VERSION ""

NS_ :

BS_:

BU_: XXX

BO_ 85 CID_YLHISD: 8 XXX
 SG_ sig_fvpfgf : 40|1@1+ (1,0) [0|1] "" XXX
 SG_ sig_tsgliz : 56|8@1+ (1,0) [0|255] "" XXX

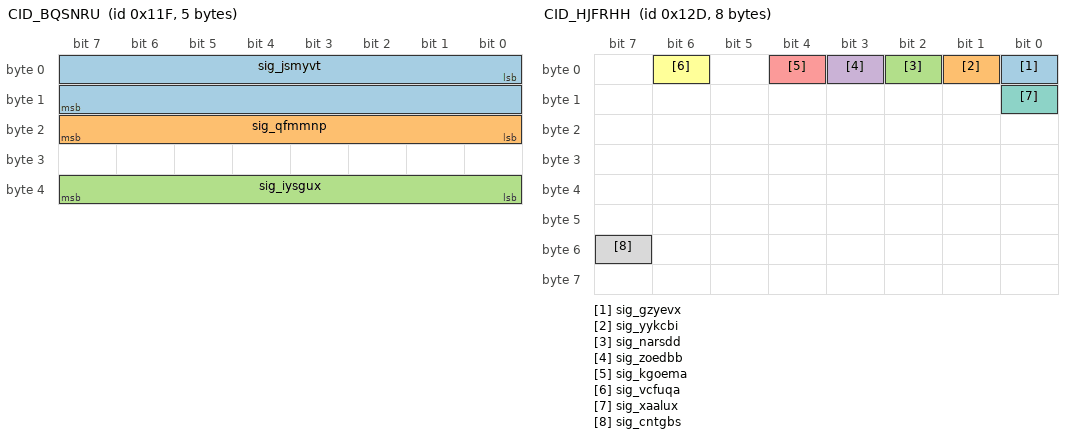
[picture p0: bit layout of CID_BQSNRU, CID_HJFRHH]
BO_ 287 CID_BQSNRU: 5 XXX
 SG_ sig_jsmyvt : 0|16@1- (0.1,0) [-450|450] "" XXX
 SG_ sig_qfmmnp : 16|8@1+ (4,0) [0|1020] "" XXX
 SG_ sig_iysgux : 32|8@1+ (1,0) [0|255] "" XXX

BO_ 289 CID_XMIBTZ: 8 XXX
 SG_ sig_dkgysv : 0|12@1+ (1,0) [0|255] "" XXX

BO_ 301 CID_HJFRHH: 8 XXX
 SG_ sig_gzyevx : 0|1@0+ (1,0) [0|1] "" XXX
 SG_ sig_yykcbi : 1|1@0+ (1,0) [0|1] "" XXX
 SG_ sig_narsdd : 2|1@0+ (1,0) [0|1] "" XXX
 SG_ sig_zoedbb : 3|1@0+ (1,0) [0|1] "" XXX
 SG_ sig_kgoema : 4|1@0+ (1,0) [0|1] "" XXX
 SG_ sig_vcfuqa : 6|1@0+ (1,0) [0|1] "" XXX
 SG_ sig_xaalux : 8|1@0+ (1,0) [0|1] "" XXX
 SG_ sig_cntgbs : 55|1@0+ (1,0) [0|1] "" XXX

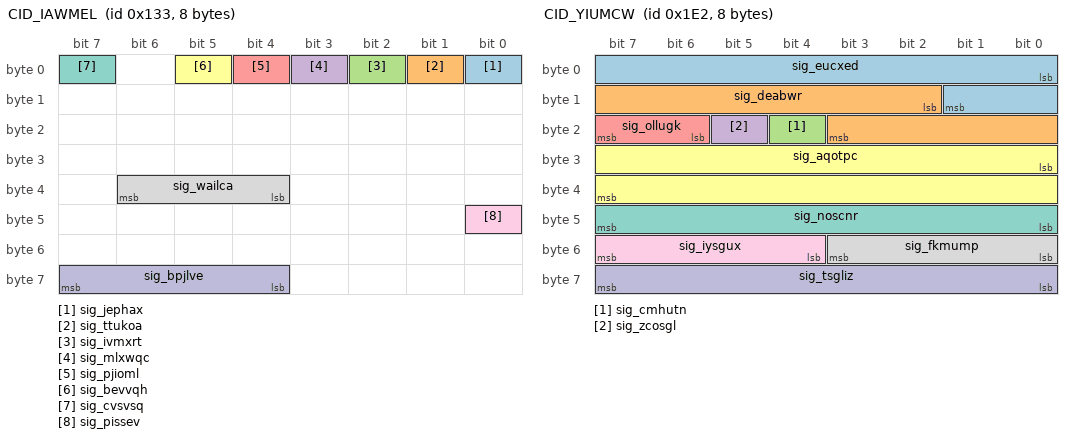
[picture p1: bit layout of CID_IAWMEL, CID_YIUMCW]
BO_ 307 CID_IAWMEL: 8 XXX
 SG_ sig_jephax : 0|1@0+ (1,0) [0|1] "" XXX
 SG_ sig_ttukoa : 1|1@1+ (1,0) [0|1] "" XXX
 SG_ sig_ivmxrt : 2|1@1+ (1,0) [0|1] "" XXX
 SG_ sig_mlxwqc : 3|1@1+ (1,0) [0|1] "" XXX
 SG_ sig_pjioml : 4|1@0+ (1,0) [0|1] "" XXX
 SG_ sig_bevvqh : 5|1@0+ (1,0) [0|1] "" XXX
 SG_ sig_cvsvsq : 7|1@0+ (1,0) [0|1] "" XXX
 SG_ sig_wailca : 36|3@1+ (1,0) [0|7] "" XXX
 SG_ sig_pissev : 40|1@0+ (1,0) [0|1] "" XXX
 SG_ sig_bpjlve : 63|4@0+ (1,0) [0|15] "" XXX

BO_ 482 CID_YIUMCW: 8 XXX
 SG_ sig_eucxed : 0|10@1- (0.01,0) [0|5] "" XXX
 SG_ sig_deabwr : 10|10@1- (0.01,0) [-5|0] "" XXX
 SG_ sig_cmhutn : 20|1@0+ (1,0) [0|1] "" XXX
 SG_ sig_zcosgl : 21|1@0+ (1,0) [0|1] "" XXX
 SG_ sig_ollugk : 22|2@1+ (1,0) [0|1] "" XXX
 SG_ sig_aqotpc : 24|16@1- (0.1,0) [-780|779.9] "" XXX
 SG_ sig_noscnr : 47|8@0+ (1,0) [0|255] "" XXX
 SG_ sig_fkmump : 48|4@1+ (1,0) [0|15] "" XXX
 SG_ sig_iysgux : 52|4@1+ (1,0) [0|15] "" XXX
 SG_ sig_tsgliz : 56|8@1+ (1,0) [0|255] "" XXX

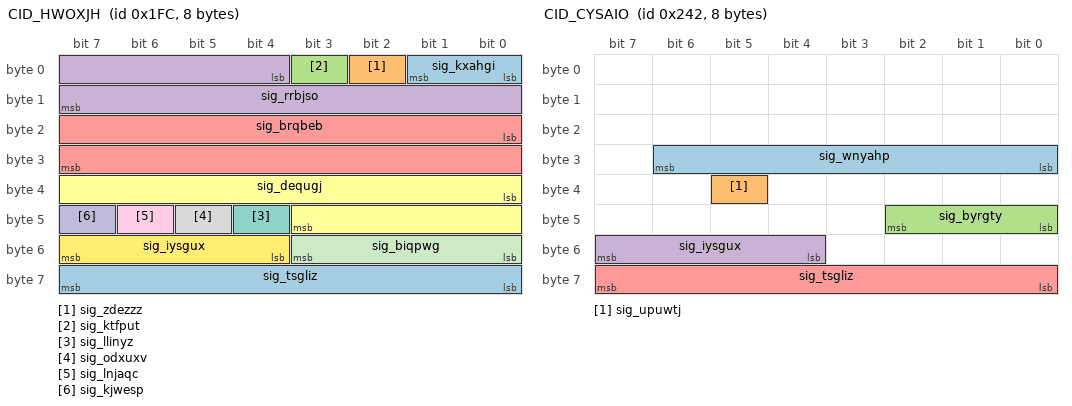
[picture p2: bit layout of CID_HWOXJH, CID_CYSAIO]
BO_ 508 CID_HWOXJH: 8 XXX
 SG_ sig_kxahgi : 0|2@1+ (1,0) [0|1] "" XXX
 SG_ sig_zdezzz : 2|1@1+ (1,0) [0|1] "" XXX
 SG_ sig_ktfput : 3|1@0+ (1,0) [0|1] "" XXX
 SG_ sig_rrbjso : 4|12@1- (1,0) [-2048|2047] "" XXX
 SG_ sig_brqbeb : 16|16@1- (0.1,0) [-780|779.9] "Deg" XXX
 SG_ sig_dequgj : 32|12@1- (0.01,0) [0|63] "" XXX
 SG_ sig_llinyz : 44|1@0+ (1,0) [0|1] "" XXX
 SG_ sig_odxuxv : 45|1@1+ (1,0) [0|255] "" XXX
 SG_ sig_lnjaqc : 46|1@1+ (1,0) [0|1] "" XXX
 SG_ sig_kjwesp : 47|1@0+ (1,0) [0|3] "" XXX
 SG_ sig_biqpwg : 48|4@1+ (1,0) [0|15] "" XXX
 SG_ sig_iysgux : 52|4@1+ (1,0) [0|15] "" XXX
 SG_ sig_tsgliz : 56|8@1+ (1,0) [0|255] "" XXX

BO_ 578 CID_CYSAIO: 8 XXX
 SG_ sig_wnyahp : 30|7@0+ (1,0) [0|127] "" XXX
 SG_ sig_upuwtj : 37|1@0+ (1,0) [0|1] "" XXX
 SG_ sig_byrgty : 40|3@1+ (1,0) [0|7] "" XXX
 SG_ sig_iysgux : 55|4@0+ (1,0) [0|15] "" XXX
 SG_ sig_tsgliz : 56|8@1+ (1,0) [0|255] "" XXX

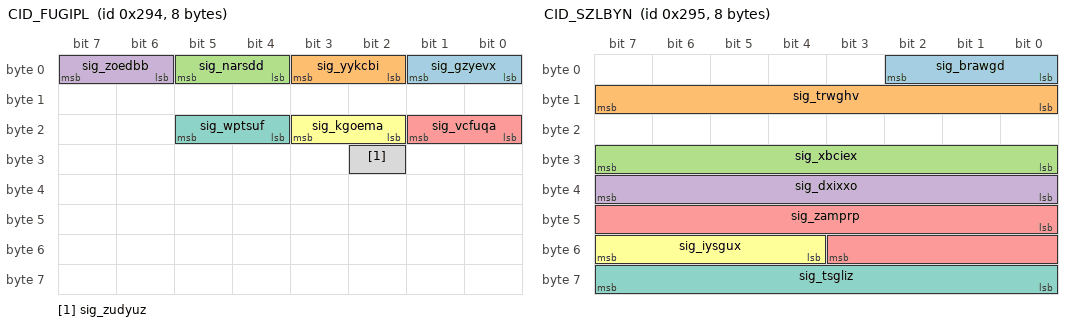
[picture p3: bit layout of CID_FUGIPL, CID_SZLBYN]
BO_ 660 CID_FUGIPL: 8 XXX
 SG_ sig_gzyevx : 1|2@0+ (1,0) [0|3] "" XXX
 SG_ sig_yykcbi : 3|2@0+ (1,0) [0|3] "" XXX
 SG_ sig_narsdd : 5|2@0+ (1,0) [0|3] "" XXX
 SG_ sig_zoedbb : 7|2@0+ (1,0) [0|3] "" XXX
 SG_ sig_vcfuqa : 17|2@0+ (1,0) [0|3] "" XXX
 SG_ sig_kgoema : 19|2@0+ (1,0) [0|3] "" XXX
 SG_ sig_wptsuf : 21|2@0+ (1,0) [0|3] "" XXX
 SG_ sig_zudyuz : 26|1@0+ (1,0) [0|1] "" XXX

BO_ 661 CID_SZLBYN: 8 XXX
 SG_ sig_brawgd : 2|3@0+ (1,0) [0|7] "" XXX
 SG_ sig_trwghv : 15|8@0+ (1,0) [0|255] "" XXX
 SG_ sig_xbciex : 31|8@0+ (1,0) [0|255] "" XXX
 SG_ sig_dxixxo : 32|8@1+ (1,0) [0|255] "" XXX
 SG_ sig_zamprp : 40|12@1+ (1,0) [0|255] "" XXX
 SG_ sig_iysgux : 52|4@1+ (1,0) [0|15] "" XXX
 SG_ sig_tsgliz : 63|8@0+ (1,0) [0|255] "" XXX

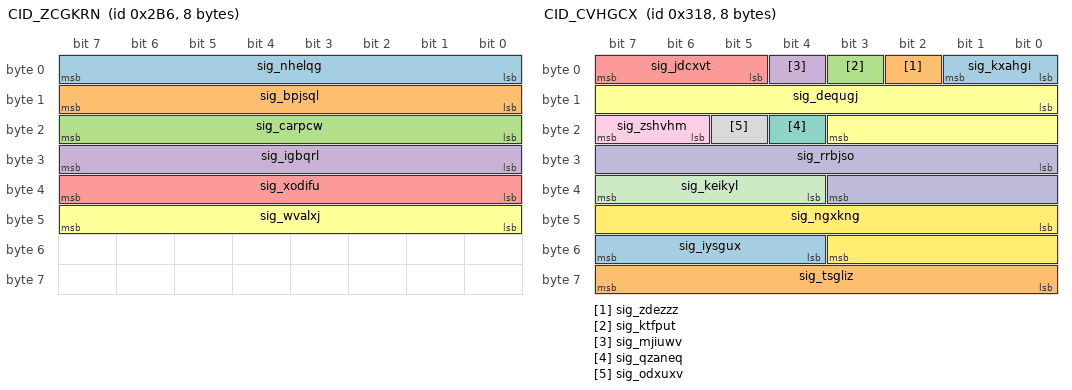
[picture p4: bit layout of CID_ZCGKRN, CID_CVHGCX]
BO_ 694 CID_ZCGKRN: 8 XXX
 SG_ sig_nhelqg : 7|8@0+ (1,0) [0|255] "" XXX
 SG_ sig_bpjsql : 15|8@0+ (1,0) [0|255] "" XXX
 SG_ sig_carpcw : 23|8@0+ (1,0) [0|255] "" XXX
 SG_ sig_igbqrl : 31|8@0+ (1,0) [0|255] "" XXX
 SG_ sig_xodifu : 39|8@0+ (1,0) [0|255] "" XXX
 SG_ sig_wvalxj : 47|8@0+ (1,0) [0|255] "" XXX

BO_ 790 CID_VGAAZI: 8 XXX
 SG_ sig_pvigeh : 3|4@0+ (1,0) [0|1] "" XXX
 SG_ sig_ayitkw : 4|2@1+ (1,0) [0|3] "" XXX
 SG_ sig_hsumzr : 6|2@1+ (1,0) [0|3] "" XXX
 SG_ sig_etynbz : 8|2@1+ (1,0) [0|3] "" XXX
 SG_ sig_iscwey : 10|1@1+ (1,0) [0|1] "" XXX
 SG_ sig_ijgjkw : 11|4@1+ (1,0) [0|1] "" XXX
 SG_ sig_yxnoho : 15|1@0+ (1,0) [0|1] "" XXX
 SG_ sig_aqotpc : 16|11@1- (1,0) [-1024|1023] "" XXX
 SG_ sig_cmhutn : 27|1@1+ (1,0) [0|1] "" XXX
 SG_ sig_zcosgl : 28|1@1+ (1,0) [0|3] "" XXX
 SG_ sig_svjvgf : 29|1@0+ (1,0) [0|1] "" XXX
 SG_ sig_kfxihe : 30|1@0+ (1,0) [0|1] "" XXX
 SG_ sig_oejzxm : 31|1@0+ (1,0) [0|1] "" XXX
 SG_ sig_uycpft : 32|2@1+ (1,0) [0|3] "" XXX
 SG_ sig_gcixse : 34|2@1+ (1,0) [0|3] "" XXX
 SG_ sig_urhqjd : 36|4@1+ (1,0) [0|3] "" XXX
 SG_ sig_iqeeie : 40|8@1+ (5,-5) [-5|1270] "" XXX
 SG_ sig_nwlxpp : 49|2@0+ (1,0) [0|3] "" XXX
 SG_ sig_gdyqsl : 51|2@0+ (1,0) [0|3] "" XXX
 SG_ sig_iysgux : 52|4@1+ (1,0) [0|15] "" XXX
 SG_ sig_tsgliz : 56|8@1+ (1,0) [0|15] "" XXX

BO_ 792 CID_CVHGCX: 8 XXX
 SG_ sig_kxahgi : 0|2@1+ (1,0) [0|1] "" XXX
 SG_ sig_zdezzz : 2|1@1+ (1,0) [0|1] "" XXX
 SG_ sig_ktfput : 3|1@1+ (1,0) [0|1] "" XXX
 SG_ sig_mjiuwv : 4|1@1+ (1,0) [0|1] "" XXX
 SG_ sig_jdcxvt : 5|3@1+ (1,0) [0|1] "" XXX
 SG_ sig_dequgj : 8|12@1- (1,0) [-2048|2047] "" XXX
 SG_ sig_qzaneq : 20|1@1+ (1,0) [0|1] "" XXX
 SG_ sig_odxuxv : 21|1@1+ (1,0) [0|1] "" XXX
 SG_ sig_zshvhm : 22|2@1+ (1,0) [0|15] "" XXX
 SG_ sig_rrbjso : 24|12@1- (1,0) [-2048|2047] "" XXX
 SG_ sig_keikyl : 36|4@1+ (1,0) [0|15] "" XXX
 SG_ sig_ngxkng : 40|12@1+ (1,0) [0|4095] "" XXX
 SG_ sig_iysgux : 52|4@1+ (1,0) [0|15] "" XXX
 SG_ sig_tsgliz : 56|8@1+ (1,0) [0|255] "" XXX

BO_ 813 CID_OEVZJV: 8 XXX
 SG_ sig_xjaqbl : 0|9@1+ (0.5,0) [0|255.5] "" XXX
 SG_ sig_zsjqvj : 9|1@1+ (1,0) [0|1] "" XXX
 SG_ sig_rfnqwn : 10|3@1+ (1,0) [0|7] "" XXX
 SG_ sig_sghgis : 13|3@1+ (1,0) [0|7] "" XXX
 SG_ sig_kxemyu : 16|1@1+ (1,0) [0|1] "" XXX
 SG_ sig_qitwor : 17|1@1+ (1,0) [0|1] "" XXX
 SG_ sig_ktfput : 18|1@1+ (1,0) [0|1] "" XXX
 SG_ sig_ioyvfd : 19|3@1+ (1,0) [0|1] "" XXX
 SG_ sig_dzvoyg : 22|1@0+ (1,0) [0|1] "" XXX
 SG_ sig_lukxbe : 23|1@0+ (1,0) [0|1] "" XXX
 SG_ sig_etynbz : 24|1@1+ (1,0) [0|1] "" XXX
 SG_ sig_clpqkk : 25|7@1+ (1,0) [0|127] "" XXX
 SG_ sig_rrhalc : 32|4@1+ (1,0) [0|15] "" XXX
 SG_ sig_luyymk : 36|12@1+ (1,0) [0|4095] "" XXX
 SG_ sig_iysgux : 48|4@1+ (1,0) [0|15] "" XXX
 SG_ sig_qbgbpz : 55|4@0+ (1,0) [0|15] "" XXX
 SG_ sig_tsgliz : 56|8@1+ (1,0) [0|255] "" XXX

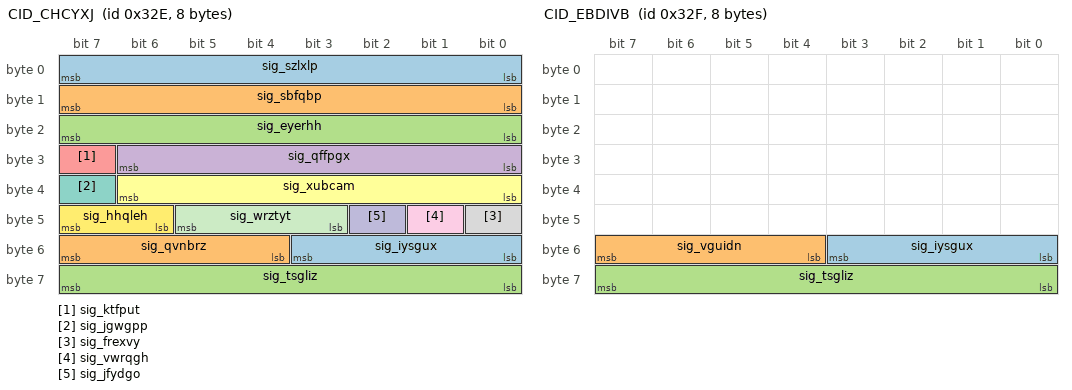
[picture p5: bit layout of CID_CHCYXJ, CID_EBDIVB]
BO_ 814 CID_CHCYXJ: 8 XXX
 SG_ sig_szlxlp : 0|8@1+ (0.05,-5) [-100|155] "" XXX
 SG_ sig_sbfqbp : 8|8@1+ (0.05,-5) [0|1.26] "" XXX
 SG_ sig_eyerhh : 16|8@1+ (0.05,-5) [0|1.26] "" XXX
 SG_ sig_qffpgx : 24|7@1+ (0.2,0) [0|12.7] "" XXX
 SG_ sig_ktfput : 31|1@0+ (1,0) [0|1] "" XXX
 SG_ sig_xubcam : 32|7@1+ (0.2,-16) [0|12.7] "" XXX
 SG_ sig_jgwgpp : 39|1@0+ (1,0) [0|1] "" XXX
 SG_ sig_frexvy : 40|1@0+ (1,0) [0|1] "" XXX
 SG_ sig_vwrqgh : 41|1@0+ (1,0) [0|1] "" XXX
 SG_ sig_jfydgo : 42|1@1+ (1,0) [0|3] "" XXX
 SG_ sig_wrztyt : 45|3@0+ (1,0) [0|1] "" XXX
 SG_ sig_hhqleh : 46|2@1+ (1,0) [0|3] "" XXX
 SG_ sig_iysgux : 48|4@1+ (1,0) [0|15] "" XXX
 SG_ sig_qvnbrz : 55|4@0+ (1,0) [0|15] "" XXX
 SG_ sig_tsgliz : 56|8@1+ (1,0) [0|255] "" XXX

BO_ 815 CID_EBDIVB: 8 XXX
 SG_ sig_iysgux : 48|4@1+ (1,0) [0|15] "" XXX
 SG_ sig_vguidn : 55|4@0+ (1,0) [0|15] "" XXX
 SG_ sig_tsgliz : 56|8@1+ (1,0) [0|255] "" XXX

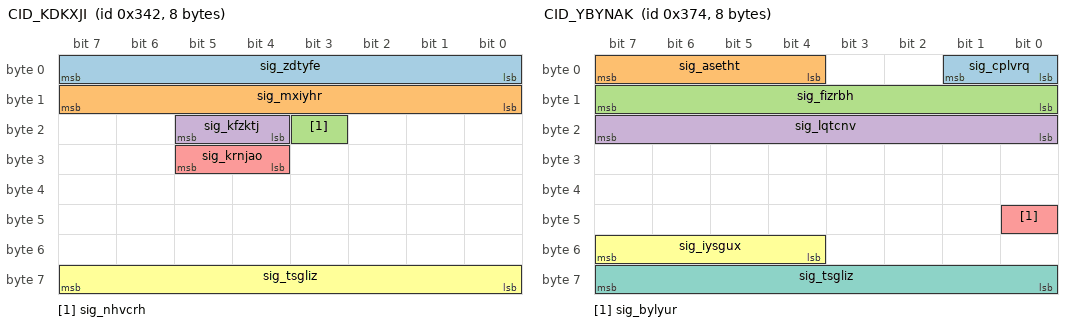
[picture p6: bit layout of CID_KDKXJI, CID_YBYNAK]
BO_ 834 CID_KDKXJI: 8 XXX
 SG_ sig_zdtyfe : 0|8@1+ (0.01,0) [0|2.55] "" XXX
 SG_ sig_mxiyhr : 8|8@1+ (0.01,0) [0|2.55] "" XXX
 SG_ sig_nhvcrh : 19|1@1+ (1,0) [0|1] "" XXX
 SG_ sig_kfzktj : 20|2@1+ (1,0) [0|255] "" XXX
 SG_ sig_krnjao : 28|2@1+ (1,0) [0|1] "" XXX
 SG_ sig_tsgliz : 56|8@1+ (1,0) [0|255] "" XXX

BO_ 884 CID_YBYNAK: 8 XXX
 SG_ sig_cplvrq : 1|2@0+ (1,0) [0|3] "" XXX
 SG_ sig_asetht : 7|4@0+ (1,0) [0|15] "" XXX
 SG_ sig_fizrbh : 15|8@0+ (0.1,-12) [0|255] "" XXX
 SG_ sig_lqtcnv : 23|8@0+ (1,-100) [0|255] "" XXX
 SG_ sig_bylyur : 40|1@0+ (1,0) [0|3] "" XXX
 SG_ sig_iysgux : 52|4@1+ (1,0) [0|15] "" XXX
 SG_ sig_tsgliz : 56|8@1+ (1,0) [0|255] "" XXX

BO_ 944 CID_MFPAKE: 8 XXX
 SG_ sig_wnytrs : 1|2@0+ (1,0) [0|3] "" XXX
 SG_ sig_wbnral : 2|1@0+ (1,0) [0|1] "" XXX
 SG_ sig_friymx : 4|2@0+ (1,0) [0|3] "" XXX
 SG_ sig_lgcnaj : 5|1@0+ (1,0) [0|1] "" XXX
 SG_ sig_eagnnp : 6|1@0+ (1,0) [0|1] "" XXX
 SG_ sig_ckrcgo : 7|1@0+ (1,0) [0|1] "" XXX
 SG_ sig_nrcvqh : 8|1@0+ (1,0) [0|1] "" XXX
 SG_ sig_ekkdfd : 11|3@0+ (1,0) [0|7] "" XXX
 SG_ sig_veofmz : 12|1@0+ (1,0) [0|1] "" XXX
 SG_ sig_rzqkqf : 14|2@0+ (1,0) [0|3] "" XXX
 SG_ sig_vvfvyf : 15|1@0+ (1,0) [0|1] "" XXX
 SG_ sig_nkmamn : 16|1@0+ (1,0) [0|1] "" XXX
 SG_ sig_njyllo : 18|2@0+ (1,0) [0|3] "" XXX
 SG_ sig_svzdxs : 19|1@0+ (1,0) [0|1] "" XXX
 SG_ sig_mcstnu : 23|4@0+ (1,0) [0|15] "" XXX
 SG_ sig_hlrtfv : 24|28@1+ (1,0) [0|268435455] "" XXX
 SG_ sig_iysgux : 52|4@1+ (1,0) [0|15] "" XXX
 SG_ sig_tsgliz : 56|8@1+ (1,0) [0|255] "" XXX

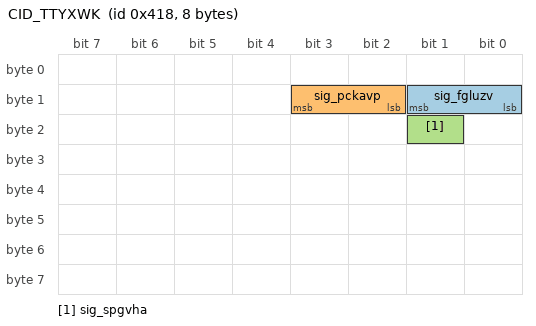
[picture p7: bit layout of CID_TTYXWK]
BO_ 1048 CID_TTYXWK: 8 XXX
 SG_ sig_fgluzv : 9|2@0+ (1,0) [0|1] "" XXX
 SG_ sig_pckavp : 11|2@0+ (1,0) [0|1] "" XXX
 SG_ sig_spgvha : 17|1@0+ (1,0) [0|1] "" XXX

VAL_ 578 sig_byrgty 4 "D" 2 "R" 3 "N" 1 "P";
VAL_ 790 sig_pvigeh 11 "AutoFullBeamActive" 2 "AutoFullBeamInactive";
VAL_ 790 sig_ayitkw 0 "GRAY" 1 "GREEN" 2 "YELLOW" 3 "RED";
VAL_ 790 sig_hsumzr 3 "ALARM_AND_LKA" 2 "LKA" 1 "ALARM" 0 "DISABLE";
VAL_ 790 sig_gcixse 0 "GRAY" 1 "GREEN" 2 "YELLOW" 3 "RED";
VAL_ 790 sig_nwlxpp 0 "VIBRATION" 1 "AUDIO" 2 "AUDIO_AND_VIBRATION";
VAL_ 792 sig_kxahgi 0 "NotReady" 1 "Ready" 2 "Active" 3 "TemporaryFail";
VAL_ 813 sig_rfnqwn 4 "4BAR" 3 "3BAR" 2 "2BAR" 1 "1BAR";
VAL_ 813 sig_ioyvfd 0 "OFF" 2 "ACC_ON" 3 "ACC_ACTIVE" 5 "FORCE_ACCEL" 7 "ERROR";
VAL_ 813 sig_clpqkk 36 "ACC_ERROR" 22 "OVERRIDE" 12 "ENGAGE" 8 "DISENGAGE" 20 "ACC_ON" 32 "ACC_OFF" 48 "CHECK_GEAR_D" 16 "FORCE_ACCEL" 0 "NONE";
VAL_ 814 sig_wrztyt 0 "Off" 1 "Passive" 2 "StandBy" 3 "ActiveControl" 4 "BrakeOnly" 5 "Override" 6 "Standstill" 7 "Failure";
VAL_ 814 sig_hhqleh 0 "Softoff" 1 "Fastoff" 2 "Immediateoff" 3 "Initial";
VAL_ 834 sig_kfzktj 2 "SPORT" 1 "ECO" 0 "SNOW";
VAL_ 834 sig_krnjao 3 "HEV" 2 "FORCE_EV" 1 "EV";
VAL_ 944 sig_friymx 0 "NOTPRESSED" 1 "DOWN_SETSPEED" 3 "UP_RESETSPEED";
